# SAM9X60 device description
Architecture: ARM926EJS; Family: SAM9; Series: SAM9X
Registers are 32-bit, read-write, no defined reset value unless marked. A register's access mark holds for its fields unless they carry their own. Offsets are from the block's base; [hi:lo] are bit positions.

## RTT — Real-time Timer
Instances: RTT 0xFFFFFE20
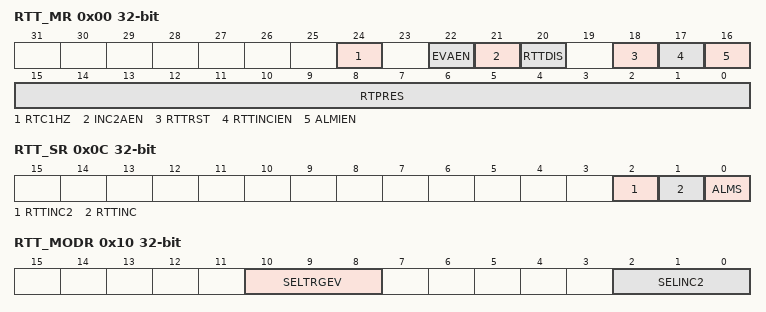
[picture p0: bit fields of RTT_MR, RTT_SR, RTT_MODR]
0x00 RTT_MR — Mode Register
  [24] RTC1HZ — Real-Time Clock 1Hz Clock Selection
  [22] EVAEN — Trigger Event Alarm Enable
  [21] INC2AEN — RTTINC2 Alarm Enable
  [20] RTTDIS — Real-time Timer Disable
  [18] RTTRST — Real-time Timer Restart
  [17] RTTINCIEN — Real-time Timer Increment Interrupt Enable
  [16] ALMIEN — Alarm Interrupt Enable
  [15:0] RTPRES — Real-time Timer Prescaler Value
0x04 RTT_AR — Alarm Register
  [31:0] ALMV — Alarm Value
0x08 RTT_VR ro — Value Register
  [31:0] CRTV — Current Real-time Value
0x0C RTT_SR ro — Status Register
  [2] RTTINC2 — Predefined Number of Prescaler Roll-overs Status (cleared on read)
  [1] RTTINC — Prescaler Roll-over Status (cleared on read)
  [0] ALMS — Real-time Alarm Status (cleared on read)
0x10 RTT_MODR — Modulo Selection Register
  [10:8] SELTRGEV — Selection of the 32-bit Counter Modulo to generate the trigger event
    0=NO_EVENT (No event generated); 1=MOD2 (Event occurs when CRTV modulo 2 equals 0); 2=MOD4 (Event occurs when CRTV modulo 4 equals 0); 3=MOD8 (Event occurs when CRTV modulo 8 equals 0); 4=MOD16 (Event occurs when CRTV modulo 16 equals 0); 5=MOD32 (Event occurs when CRTV modulo 32 equals 0); 6=MOD64 (Event occurs when CRTV modulo 64 equals 0); 7=MOD128 (Event occurs when CRTV modulo 128 equals 0)
  [2:0] SELINC2 — Selection of the 32-bit Counter Modulo to generate RTTINC2 flag
    0=NO_RTTINC2 (The RTTINC2 flag never rises); 1=MOD64 (The RTTINC2 flag is set when CRTV modulo 64 equals 0); 2=MOD128 (The RTTINC2 flag is set when CRTV modulo 128 equals 0); 3=MOD256 (The RTTINC2 flag is set when CRTV modulo 256 equals 0); 4=MOD512 (The RTTINC2 flag is set when CRTV modulo 512 equals 0); 5=MOD1024 (The RTTINC2 flag is set when CRTV modulo 1024 equals 0. Example: If RTPRES=32 then RTTINC2 flag rises once per second if the slow clock is 32.768 kHz.); 6=MOD2048 (The RTTINC2 flag is set when CRTV modulo 2048 equals 0); 7=MOD4096 (The RTTINC2 flag is set when CRTV modulo 4096 equals 0)
0x14 RTT_TSR ro — TimeStamp Register
  [23:0] TSTAMP — Real-time Timer Value Timestamp

## SCKC — Slow Clock Controller
Instances: SCKC 0xFFFFFE50
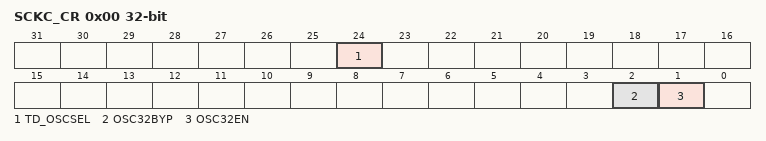
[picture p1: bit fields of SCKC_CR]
0x00 SCKC_CR — Slow Clock Controller Configuration Register
  [24] TD_OSCSEL — Timing Domain Slow Clock Selector
    0=RC (Slow clock of the timing domain is driven by the embedded 32 kHz (typical) RC oscillator.); 1=XTAL (Slow clock of the timing domain is driven by the 32.768 kHz crystal oscillator.)
  [2] OSC32BYP — 32.768 kHz Crystal Oscillator Bypass
  [1] OSC32EN — 32.768 kHz Crystal Oscillator

## SHDWC — Shutdown Controller
Instances: SHDWC 0xFFFFFE10
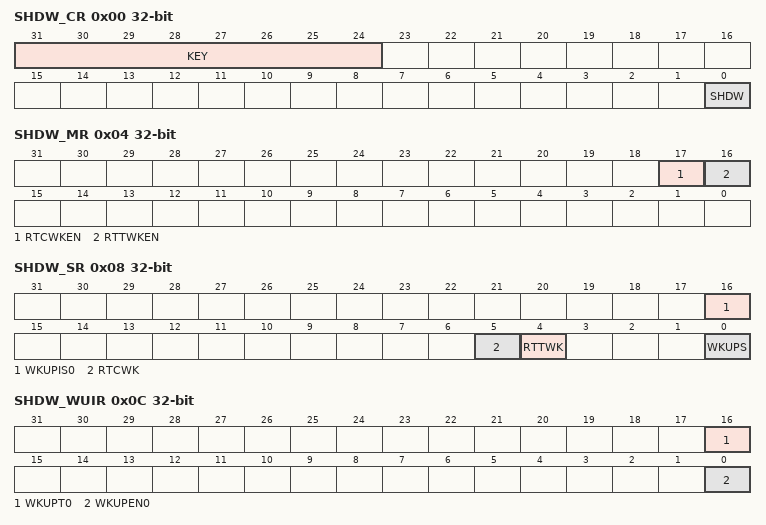
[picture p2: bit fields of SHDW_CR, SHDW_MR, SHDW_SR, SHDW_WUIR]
0x00 SHDW_CR wo — Control Register
  [31:24] KEY — Password
    165=PASSWD (Writing any other value in this field aborts the write operation.)
  [0] SHDW — Shutdown Command
0x04 SHDW_MR — Mode Register
  [17] RTCWKEN — Real-time Clock Wakeup Enable
  [16] RTTWKEN — Real-time Timer Wakeup Enable
0x08 SHDW_SR ro — Status Register
  [16] WKUPIS0 — Wakeup 0 Input Status
    0=DISABLE (The wakeup 0 input is disabled, or was inactive at the time the debouncer triggered a wakeup event.); 1=ENABLE (The wakeup 0 input was active at the time the debouncer triggered a wakeup event.)
  [5] RTCWK — Real-time Clock Wakeup
  [4] RTTWK — Real-time Timer Wakeup
  [0] WKUPS — PIOBU, WKUP Wakeup Status
    0=NO (No wakeup due to the assertion of the PIOBU, WKUP pins has occurred since the last read of SHDW_SR.); 1=PRESENT (At least one wakeup due to the assertion of the PIOBU, WKUP pins has occurred since the last read of SHDW_SR.)
0x0C SHDW_WUIR — Wakeup Inputs Register
  [16] WKUPT0 — Wakeup 0 Input Type
    0=LOW (A falling edge followed by a low level on the wakeup 0 input, for a period defined by WKUPDBC, forces wakeup of the core power supply.); 1=HIGH (A rising edge followed by a high level on the wakeup 0 input, for a period defined by WKUPDBC, forces wakeup of the core power supply.)
  [0] WKUPEN0 — Wakeup 0 Input Enable
    0=DISABLE (The wakeup 0 input has no wakeup effect.); 1=ENABLE (The wakeup 0 input forces wakeup of the core power supply.)
